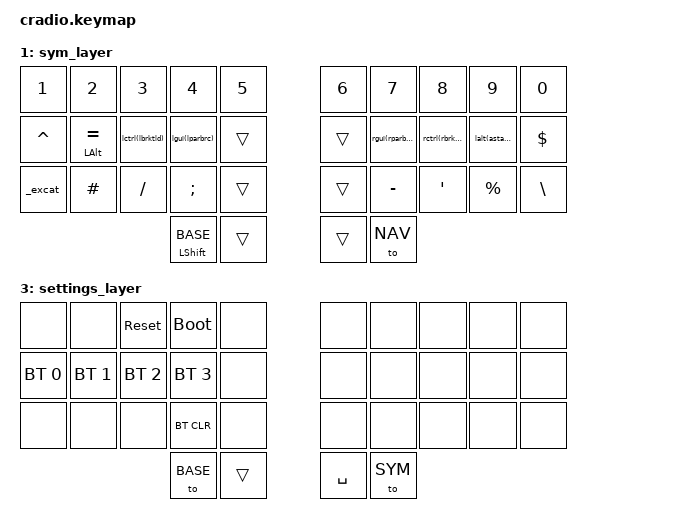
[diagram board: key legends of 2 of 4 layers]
// Copyright (c) 2022 The ZMK Contributors
// SPDX-License-Identifier: MIT

#include <behaviors.dtsi>
#include <dt-bindings/zmk/keys.h>
#include <dt-bindings/zmk/bt.h>

// Layer definitions
#define BASE     0
#define SYM      1
#define NAV      2
#define SETTINGS 3

// Home row mods macro
#define lalt(ht)  &ht LALT  0
#define lctrl(ht) &ht LCTRL 0
#define lgui(ht)  &ht LGUI  0
#define rctrl(ht) &ht RCTRL 0
#define rgui(ht)  &ht RGUI  0

#define HRML(k1,k2,k3) &lht LALT     k1  &lht LCTRL k2  &lht LGUI  k3
#define HRMR(k1,k2,k3) &rht RGUI     k1  &rht RCTRL k2  &rht LALT  k3

// Hold to shift, tap to go to BASE layer
#define SHIFT &hl LSHIFT BASE

// (Alphas) Cluster definitions
#define RHS    5  6  7  8  9 \
              15 16 17 18 19 \
              25 26 27 28 29

#define LHS    0  1  2  3  4 \
              10 11 12 13 14 \
              20 21 22 23 24

// Used to generate combos/alternate shift keycodes
#define COMBO(code, name, k1, k2) \
  _##code: _##name { \
    compatible = "zmk,behavior-mod-morph"; \
    #binding-cells = <0>; \
    bindings = <&kp k1>, <&kp k2>; \
    mods = <(MOD_LSFT)>; \
  }; \
  code: name { \
    compatible = "zmk,behavior-hold-tap"; \
    #binding-cells = <2>; \
    flavor = "tap-preferred"; \
    tapping-term-ms = <175>; \
    require-prior-idle-ms = <100>; \
    quick-tap-ms = <50>; \
    bindings = <&kp>, <&_##code>; \
    hold-trigger-key-positions = <RHS 31>; \
  }

/ {
    behaviors {
        // left-hold-tap
        lht: left_hold_tap {
            compatible = "zmk,behavior-hold-tap";
            #binding-cells = <2>;
            flavor = "balanced";
            tapping-term-ms = <175>;
            require-prior-idle-ms = <100>;
            quick-tap-ms = <50>;
            bindings = <&kp>, <&kp>;
            // Hold trigger on opposite side, RHS and tab
            hold-trigger-key-positions = <RHS 31>;
        };

        // left-hold-tap
        rht: right_hold_tap {
            compatible = "zmk,behavior-hold-tap";
            #binding-cells = <2>;
            flavor = "balanced";
            tapping-term-ms = <175>;
            require-prior-idle-ms = <100>;
            quick-tap-ms = <50>;
            bindings = <&kp>, <&kp>;
            // Hold trigger on opposite side, LHS and tab
            hold-trigger-key-positions = <LHS 31>;
        };

        // Used for shift
        hl: hold_layer {
            compatible = "zmk,behavior-hold-tap";
            flavor = "tap-preferred";
            #binding-cells = <2>;
            tapping-term-ms = <220>;
            quick-tap-ms = <190>;
            bindings = <&kp>, <&to>;
        };

        // Backspace / delete
        bsp: backspace_delete {
            compatible = "zmk,behavior-mod-morph";
            #binding-cells = <0>;
            bindings = <&kp BACKSPACE>, <&kp DELETE>;
            mods = <(MOD_LSFT)>;
        };

        // [ ~
        COMBO(lbrktld, leftbracket_tilde,  LEFT_BRACKET,  TILDE);

        // ] `
        COMBO(rbrkgrv, rightbracket_grave, RIGHT_BRACKET, GRAVE);

        // ( {
        COMBO(lparbrc, leftpar_brace,  LEFT_PARENTHESIS,  LEFT_BRACE);
        // ) }
        COMBO(rparbrc, rightpar_brace, RIGHT_PARENTHESIS, RIGHT_BRACE);

        // * &
        COMBO(astamp, asterisk_ampersand,  ASTERISK,    AMPERSAND);
        // ! @
        COMBO(excat,  exclamation_at,      EXCLAMATION, AT_SIGN);
    };

    macros {
        esc: esc {
            label = "esc";
            compatible = "zmk,behavior-macro";
            #binding-cells = <0>;
            bindings
                = <&macro_tap &kp ESC>
                , <&macro_tap &to BASE>
                ;
        };
    };

    combos {
      compatible = "zmk,combos";
      combo_compose {
        timeout-ms = <150>;
        // tab + space
        key-positions = <31 32>;
        bindings = <&kp RALT>;
        layers = <BASE SYM NAV>;
      };

      combo_esc {
        timeout-ms = <150>;
        // lshift + sym
        key-positions = <30 33>;
        bindings = <&esc>;
        layers = <BASE SYM NAV>;
      };

      // Combo for settings layer
      combo_settings {
        timeout-ms = <150>;
        // t + y
        key-positions = <4 5>;
        bindings = <&to SETTINGS>;
        layers = <NAV>;
      };
    };

    keymap {
        compatible = "zmk,keymap";
        // BASE
        default_layer {
            bindings = <
        //╭──────────┬──────────┬──────────┬──────────┬──────────╮   ╭──────────┬──────────┬──────────┬──────────┬──────────╮
        //│  B       │  Y       │  O       │  U       │  Z       │   │  Q       │  L       │  D       │  W       │  V       │
            &kp B      &kp Y      &kp O      &kp U      &kp Z          &kp Q      &kp L      &kp D      &kp W      &kp V
        //├──────────┼──────────┼──────────┼──────────┼──────────┤   ├──────────┼──────────┼──────────┼──────────┼──────────┤
        //│  C       │  I       │  E       │  A       │  , <     │   │  . >     │  H       │  T       │  S       │  N       │
            &kp C  HRML(I,         E,         A)        &kp COMMA      &kp DOT HRMR(H,        T,         S)        &kp N
        //├──────────┼──────────┼──────────┼──────────┼──────────┤   ├──────────┼──────────┼──────────┼──────────┼──────────┤
        //│  G       │  X       │  J       │  K       │  BSPC    │   │  ENTER   │  R       │  M       │  F       │  P       │
            &kp G      &kp X      &kp J      &kp K      &bsp           &kp ENTER  &kp R      &kp M      &kp F      &kp P
        //╰──────────┴──────────┴──────────┼──────────┼──────────┤   ├──────────┼──────────┼──────────┴──────────┴──────────╯
                                             &kp LSHIFT &kp TAB        &kp SPACE  &to SYM
        //                                 ╰──────────┴──────────╯   ╰──────────┴──────────╯
            >;
        };

        // SYM
        // Same as the howrow mods in BASE and NAV laver, but with different
        // hold-tap behaviours, to accomodate the shift-behaviour.
        sym_layer {
            bindings = <
        //╭──────────┬──────────┬──────────┬──────────┬──────────╮   ╭──────────┬──────────┬──────────┬──────────┬──────────╮
        //│  1       │  2       │  3       │  4       │  5       │   │  6       │  7       │  8       │  9       │  0       │
            &kp N1     &kp N2     &kp N3     &kp N4     &kp N5         &kp N6     &kp N7     &kp N8     &kp N9     &kp N0
        //├──────────┼──────────┼──────────┼──────────┼──────────┤   ├──────────┼──────────┼──────────┼──────────┼──────────┤
        //│  ^       │  = +     │  [ ~     │  ( {     │  , <     │   │  . >     │  ) }     │  ] `     │  * &     │  $       │
            &kp CARET &lht LALT EQUAL lctrl(lbrktld) lgui(lparbrc)   &trans
                                                                       &trans rgui(rparbrc) rctrl(rbrkgrv)  lalt(astamp)  &kp DLLR
        //├──────────┼──────────┼──────────┼──────────┼──────────┤   ├──────────┼──────────┼──────────┼──────────┼──────────┤
        //│  ! @     │  #       │  / ?     │  ; :     │  BSPS    │   │  ENTER   │  - _     │  ' "     │  %       │  \ |     │
            &_excat    &kp POUND   &kp FSLH   &kp SEMI   &trans         &trans     &kp MINUS  &kp SQT    &kp PRCNT  &kp BSLH
        //╰──────────┴──────────┴──────────┼──────────┼──────────┤   ├──────────┼──────────┼──────────┴──────────┴──────────╯
                                             SHIFT      &trans         &trans     &to NAV
        //                                 ╰──────────┴──────────╯   ╰──────────┴──────────╯
            >;
        };

        // NAV
        nav_layer {
            bindings = <
        //╭──────────┬──────────┬──────────┬──────────┬──────────╮   ╭──────────┬──────────┬──────────┬──────────┬──────────╮
        //│          │          │          │          │          │   │          │          │          │          │          │
            &kp F1     &kp F2     &kp F3     &kp F4     &kp F5         &kp HOME   &kp PG_DN  &kp PG_UP  &kp END    &none
        //├──────────┼──────────┼──────────┼──────────┼──────────┤   ├──────────┼──────────┼──────────┼──────────┼──────────┤
        //│          │          │          │          │          │   │  ←       │  ↓       │  ↑       │  →       │          │
            &kp F6    HRML(F7,        F8,        F9)    &kp F10        &kp LEFT   HRMR(DOWN,    UP,     RIGHT)     &none
        //├──────────┼──────────┼──────────┼──────────┼──────────┤   ├──────────┼──────────┼──────────┼──────────┼──────────┤
        //│          │          │          │          │          │   │          │          │          │          │          │
            &kp F11    &kp F12    &kp F13    &kp F14    &kp F15        &none      &none      &none      &none      &none
        //╰──────────┴──────────┴──────────┼──────────┼──────────┤   ├──────────┼──────────┼──────────┴──────────┴──────────╯
                                             SHIFT      &trans         &trans     &to SYM
        //                                 ╰──────────┴──────────╯   ╰──────────┴──────────╯
            >;
        };

        // SETTINGS
        settings_layer {
            bindings = <
        //╭──────────┬──────────┬──────────┬──────────┬──────────╮   ╭──────────┬──────────┬──────────┬──────────┬──────────╮
        //│          │          │  RESET   │BOOTLOADER│          │   │          │          │          │          │          │
            &none      &none     &sys_reset  &bootloader &none         &none      &none      &none      &none      &none
        //├──────────┼──────────┼──────────┼──────────┼──────────┤   ├──────────┼──────────┼──────────┼──────────┼──────────┤
        //│ Profile 1│          │          │          │PROFILE 1 │   │          │          │          │          │          │
          &bt BT_SEL 0 &bt BT_SEL 1 &bt BT_SEL 2  &bt BT_SEL 3 &none   &none      &none      &none      &none      &none
        //├──────────┼──────────┼──────────┼──────────┼──────────┤   ├──────────┼──────────┼──────────┼──────────┼──────────┤
        //│          │          │          │ CLEAR BT │          │   │          │          │          │          │          │
            &none      &none      &none     &bt BT_CLR  &none          &none      &none      &none      &none      &none
        //╰──────────┴──────────┴──────────┼──────────┼──────────┤   ├──────────┼──────────┼──────────┴──────────┴──────────╯
                                             &to BASE  &trans         &kp SPACE  &to SYM
        //                                 ╰──────────┴──────────╯   ╰──────────┴──────────╯
            >;
        };
    };
};
